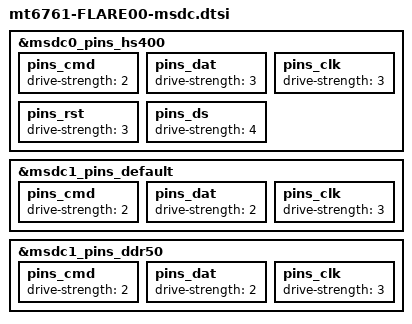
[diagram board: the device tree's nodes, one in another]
/*
 * This software is contributed or developed by KYOCERA Corporation.
 * (C) 2019 KYOCERA Corporation
 *
 * This program is free software; you can redistribute it and/or modify
 * it under the terms of the GNU General Public License version 2 and
 * only version 2 as published by the Free Software Foundation.
 *
 * This program is distributed in the hope that it will be useful,
 * but WITHOUT ANY WARRANTY; without even the implied warranty of
 * MERCHANTABILITY or FITNESS FOR A PARTICULAR PURPOSE.  See the
 * GNU General Public License for more details.
 */

&msdc0_pins_hs400  {
	pins_cmd {
		drive-strength = /bits/ 8 <2>;
		};
	pins_dat {
		drive-strength = /bits/ 8 <3>;
		};
	pins_clk {
		drive-strength = /bits/ 8 <3>;
		};
	pins_rst {
		drive-strength = /bits/ 8 <3>;
		};
	pins_ds {
		drive-strength = /bits/ 8 <4>;
		};
	};


&msdc1_pins_default {

	pins_cmd {
		drive-strength = /bits/ 8 <2>;
	};
	pins_dat {
		drive-strength = /bits/ 8 <2>;
	};
	pins_clk {
		drive-strength = /bits/ 8 <3>;
	};
};

&msdc1_pins_ddr50 {

	pins_cmd {
		drive-strength = /bits/ 8 <2>;
	};
	pins_dat {
		drive-strength = /bits/ 8 <2>;
	};
	pins_clk {
		drive-strength = /bits/ 8 <3>;
	};
};

